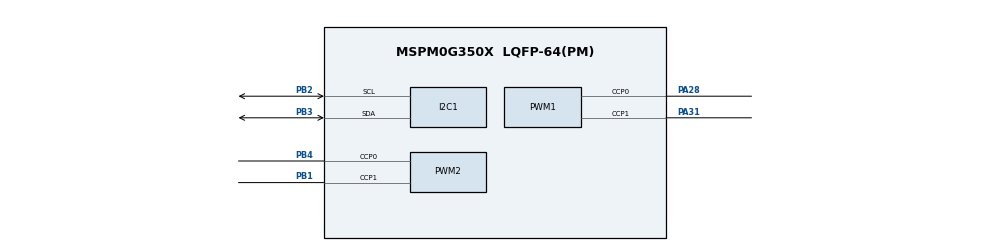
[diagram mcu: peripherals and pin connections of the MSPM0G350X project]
/**
 * @cliArgs --device "MSPM0G350X" --part "Default" --package "LQFP-64(PM)" --product "mspm0_sdk@2.05.01.01"
 * @versions {"tool":"1.24.0+4110"}
 */

/**
 * Import the modules used in this configuration.
 */
const GPIO          = scripting.addModule("/ti/driverlib/GPIO", {}, false);
const GPIO1         = GPIO.addInstance();
const GPIO2         = GPIO.addInstance();
const GPIO3         = GPIO.addInstance();
const GPIO4         = GPIO.addInstance();
const GPIO5         = GPIO.addInstance();
const GPIO6         = GPIO.addInstance();
const GPIO7         = GPIO.addInstance();
const GPIO8         = GPIO.addInstance();
const I2C           = scripting.addModule("/ti/driverlib/I2C", {}, false);
const I2C1          = I2C.addInstance();
const PWM           = scripting.addModule("/ti/driverlib/PWM", {}, false);
const PWM1          = PWM.addInstance();
const PWM2          = PWM.addInstance();
const SYSCTL        = scripting.addModule("/ti/driverlib/SYSCTL");
const TIMER         = scripting.addModule("/ti/driverlib/TIMER", {}, false);
const TIMER1        = TIMER.addInstance();
const TIMER2        = TIMER.addInstance();
const ProjectConfig = scripting.addModule("/ti/project_config/ProjectConfig");

/**
 * Write custom configuration values to the imported modules.
 */
GPIO1.$name                              = "GPIO_LED";
GPIO1.associatedPins.create(4);
GPIO1.associatedPins[0].$name            = "PIN_LED_1";
GPIO1.associatedPins[0].internalResistor = "PULL_UP";
GPIO1.associatedPins[0].assignedPort     = "PORTB";
GPIO1.associatedPins[0].assignedPin      = "22";
GPIO1.associatedPins[1].initialValue     = "SET";
GPIO1.associatedPins[1].assignedPort     = "PORTB";
GPIO1.associatedPins[1].$name            = "PIN_LED_2";
GPIO1.associatedPins[1].internalResistor = "PULL_UP";
GPIO1.associatedPins[1].assignedPin      = "26";
GPIO1.associatedPins[2].$name            = "PIN_LED_3";
GPIO1.associatedPins[2].internalResistor = "PULL_UP";
GPIO1.associatedPins[2].assignedPort     = "PORTB";
GPIO1.associatedPins[2].assignedPin      = "27";
GPIO1.associatedPins[3].assignedPort     = "PORTA";
GPIO1.associatedPins[3].assignedPin      = "13";
GPIO1.associatedPins[3].$name            = "LIGHT";

const Board = scripting.addModule("/ti/driverlib/Board", {}, false);

GPIO2.$name                              = "GPIO_KEY";
GPIO2.associatedPins.create(5);
GPIO2.associatedPins[0].$name            = "PIN_KEY_S2";
GPIO2.associatedPins[0].direction        = "INPUT";
GPIO2.associatedPins[0].assignedPort     = "PORTB";
GPIO2.associatedPins[0].assignedPin      = "21";
GPIO2.associatedPins[0].internalResistor = "PULL_UP";
GPIO2.associatedPins[1].$name            = "PIN_Key_K1";
GPIO2.associatedPins[1].direction        = "INPUT";
GPIO2.associatedPins[1].internalResistor = "PULL_UP";
GPIO2.associatedPins[1].assignedPort     = "PORTA";
GPIO2.associatedPins[1].assignedPin      = "15";
GPIO2.associatedPins[2].$name            = "PIN_Key_K2";
GPIO2.associatedPins[2].direction        = "INPUT";
GPIO2.associatedPins[2].internalResistor = "PULL_UP";
GPIO2.associatedPins[2].assignedPort     = "PORTA";
GPIO2.associatedPins[2].assignedPin      = "17";
GPIO2.associatedPins[3].$name            = "PIN_Key_K3";
GPIO2.associatedPins[3].direction        = "INPUT";
GPIO2.associatedPins[3].internalResistor = "PULL_UP";
GPIO2.associatedPins[3].assignedPort     = "PORTA";
GPIO2.associatedPins[3].assignedPin      = "24";
GPIO2.associatedPins[4].$name            = "PIN_Key_K4";
GPIO2.associatedPins[4].direction        = "INPUT";
GPIO2.associatedPins[4].internalResistor = "PULL_UP";
GPIO2.associatedPins[4].assignedPort     = "PORTB";
GPIO2.associatedPins[4].assignedPin      = "18";

GPIO3.$name                               = "GPIO_Motor_EXTI";
GPIO3.associatedPins.create(2);
GPIO3.associatedPins[0].assignedPort      = "PORTB";
GPIO3.associatedPins[0].assignedPin       = "20";
GPIO3.associatedPins[0].$name             = "M1_exti";
GPIO3.associatedPins[0].direction         = "INPUT";
GPIO3.associatedPins[0].interruptEn       = true;
GPIO3.associatedPins[0].interruptPriority = "1";
GPIO3.associatedPins[0].polarity          = "RISE";
GPIO3.associatedPins[0].internalResistor  = "PULL_DOWN";
GPIO3.associatedPins[1].$name             = "M2_exti";
GPIO3.associatedPins[1].direction         = "INPUT";
GPIO3.associatedPins[1].assignedPort      = "PORTB";
GPIO3.associatedPins[1].assignedPin       = "13";
GPIO3.associatedPins[1].interruptEn       = true;
GPIO3.associatedPins[1].interruptPriority = "1";
GPIO3.associatedPins[1].polarity          = "RISE";
GPIO3.associatedPins[1].internalResistor  = "PULL_DOWN";

GPIO4.$name                              = "GPIO_Grey";
GPIO4.associatedPins.create(8);
GPIO4.associatedPins[0].direction        = "INPUT";
GPIO4.associatedPins[0].internalResistor = "PULL_UP";
GPIO4.associatedPins[0].assignedPort     = "PORTB";
GPIO4.associatedPins[0].$name            = "PIN_Grey_0";
GPIO4.associatedPins[0].assignedPin      = "16";
GPIO4.associatedPins[1].direction        = "INPUT";
GPIO4.associatedPins[1].internalResistor = "PULL_UP";
GPIO4.associatedPins[1].assignedPort     = "PORTB";
GPIO4.associatedPins[1].$name            = "PIN_Grey_1";
GPIO4.associatedPins[1].assignedPin      = "0";
GPIO4.associatedPins[2].direction        = "INPUT";
GPIO4.associatedPins[2].internalResistor = "PULL_UP";
GPIO4.associatedPins[2].assignedPort     = "PORTB";
GPIO4.associatedPins[2].assignedPin      = "6";
GPIO4.associatedPins[2].$name            = "PIN_Grey_2";
GPIO4.associatedPins[3].direction        = "INPUT";
GPIO4.associatedPins[3].internalResistor = "PULL_UP";
GPIO4.associatedPins[3].assignedPort     = "PORTB";
GPIO4.associatedPins[3].$name            = "PIN_Grey_3";
GPIO4.associatedPins[3].assignedPin      = "7";
GPIO4.associatedPins[4].direction        = "INPUT";
GPIO4.associatedPins[4].internalResistor = "PULL_UP";
GPIO4.associatedPins[4].assignedPort     = "PORTB";
GPIO4.associatedPins[4].$name            = "PIN_Grey_4";
GPIO4.associatedPins[4].assignedPin      = "8";
GPIO4.associatedPins[5].$name            = "PIN_Grey_5";
GPIO4.associatedPins[5].direction        = "INPUT";
GPIO4.associatedPins[5].internalResistor = "PULL_UP";
GPIO4.associatedPins[5].assignedPort     = "PORTB";
GPIO4.associatedPins[5].assignedPin      = "19";
GPIO4.associatedPins[6].$name            = "PIN_Grey_6";
GPIO4.associatedPins[6].direction        = "INPUT";
GPIO4.associatedPins[6].internalResistor = "PULL_UP";
GPIO4.associatedPins[6].assignedPort     = "PORTA";
GPIO4.associatedPins[6].assignedPin      = "16";
GPIO4.associatedPins[7].$name            = "PIN_Grey_7";
GPIO4.associatedPins[7].direction        = "INPUT";
GPIO4.associatedPins[7].internalResistor = "PULL_UP";
GPIO4.associatedPins[7].assignedPort     = "PORTB";
GPIO4.associatedPins[7].assignedPin      = "12";

GPIO5.$name                          = "GPIO_Encoder";
GPIO5.associatedPins.create(2);
GPIO5.associatedPins[0].assignedPort = "PORTB";
GPIO5.associatedPins[0].$name        = "PIN_Encoder1";
GPIO5.associatedPins[0].assignedPin  = "15";
GPIO5.associatedPins[1].$name        = "PIN_Encoder2";
GPIO5.associatedPins[1].assignedPort = "PORTB";
GPIO5.associatedPins[1].assignedPin  = "17";

GPIO6.$name                          = "GPIO_Motor";
GPIO6.associatedPins.create(4);
GPIO6.associatedPins[0].$name        = "PIN_Motor1_1";
GPIO6.associatedPins[0].assignedPin  = "8";
GPIO6.associatedPins[0].assignedPort = "PORTA";
GPIO6.associatedPins[1].assignedPin  = "26";
GPIO6.associatedPins[1].assignedPort = "PORTA";
GPIO6.associatedPins[1].$name        = "PIN_Motor1_2";
GPIO6.associatedPins[2].$name        = "PIN_Motor2_1";
GPIO6.associatedPins[2].assignedPort = "PORTB";
GPIO6.associatedPins[2].assignedPin  = "24";
GPIO6.associatedPins[3].$name        = "PIN_Motor2_2";
GPIO6.associatedPins[3].assignedPort = "PORTB";
GPIO6.associatedPins[3].assignedPin  = "9";

GPIO7.$name                          = "GPIO_OLED";
GPIO7.associatedPins.create(2);
GPIO7.associatedPins[0].$name        = "OLED_SDA";
GPIO7.associatedPins[0].initialValue = "SET";
GPIO7.associatedPins[0].assignedPort = "PORTA";
GPIO7.associatedPins[0].assignedPin  = "25";
GPIO7.associatedPins[1].$name        = "OLED_SCL";
GPIO7.associatedPins[1].initialValue = "SET";
GPIO7.associatedPins[1].assignedPin  = "9";
GPIO7.associatedPins[1].assignedPort = "PORTA";

GPIO8.$name                          = "GPIO_Beep";
GPIO8.associatedPins[0].$name        = "Beep";
GPIO8.associatedPins[0].initialValue = "SET";
GPIO8.associatedPins[0].assignedPort = "PORTA";
GPIO8.associatedPins[0].assignedPin  = "12";

I2C1.$name                             = "I2C_MPU6050";
I2C1.basicEnableController             = true;
I2C1.intController                     = ["ARBITRATION_LOST","NACK","RXFIFO_TRIGGER","RX_DONE","TX_DONE"];
I2C1.peripheral.$assign                = "I2C1";
I2C1.peripheral.sdaPin.$assign         = "PB3";
I2C1.peripheral.sclPin.$assign         = "PB2";
I2C1.sdaPinConfig.hideOutputInversion  = scripting.forceWrite(false);
I2C1.sdaPinConfig.onlyInternalResistor = scripting.forceWrite(false);
I2C1.sdaPinConfig.passedPeripheralType = scripting.forceWrite("Digital");
I2C1.sdaPinConfig.$name                = "ti_driverlib_gpio_GPIOPinGeneric4";
I2C1.sclPinConfig.hideOutputInversion  = scripting.forceWrite(false);
I2C1.sclPinConfig.onlyInternalResistor = scripting.forceWrite(false);
I2C1.sclPinConfig.passedPeripheralType = scripting.forceWrite("Digital");
I2C1.sclPinConfig.$name                = "ti_driverlib_gpio_GPIOPinGeneric5";

PWM1.$name                              = "PWM_Motor";
PWM1.timerStartTimer                    = true;
PWM1.timerCount                         = 3200;
PWM1.peripheral.$assign                 = "TIMG7";
PWM1.peripheral.ccp0Pin.$assign         = "PA28";
PWM1.peripheral.ccp1Pin.$assign         = "PA31";
PWM1.PWM_CHANNEL_0.$name                = "ti_driverlib_pwm_PWMTimerCC0";
PWM1.PWM_CHANNEL_1.$name                = "ti_driverlib_pwm_PWMTimerCC1";
PWM1.ccp0PinConfig.direction            = scripting.forceWrite("OUTPUT");
PWM1.ccp0PinConfig.hideOutputInversion  = scripting.forceWrite(false);
PWM1.ccp0PinConfig.onlyInternalResistor = scripting.forceWrite(false);
PWM1.ccp0PinConfig.passedPeripheralType = scripting.forceWrite("Digital");
PWM1.ccp0PinConfig.$name                = "ti_driverlib_gpio_GPIOPinGeneric0";
PWM1.ccp1PinConfig.direction            = scripting.forceWrite("OUTPUT");
PWM1.ccp1PinConfig.hideOutputInversion  = scripting.forceWrite(false);
PWM1.ccp1PinConfig.onlyInternalResistor = scripting.forceWrite(false);
PWM1.ccp1PinConfig.passedPeripheralType = scripting.forceWrite("Digital");
PWM1.ccp1PinConfig.$name                = "ti_driverlib_gpio_GPIOPinGeneric1";

PWM2.$name                              = "PWM_Servo";
PWM2.clockDivider                       = 2;
PWM2.timerStartTimer                    = true;
PWM2.timerCount                         = 20000;
PWM2.clockPrescale                      = 16;
PWM2.pwmMode                            = "EDGE_ALIGN_UP";
PWM2.peripheral.$assign                 = "TIMA1";
PWM2.peripheral.ccp0Pin.$assign         = "PB4";
PWM2.peripheral.ccp1Pin.$assign         = "PB1";
PWM2.PWM_CHANNEL_0.$name                = "ti_driverlib_pwm_PWMTimerCC0_COPY";
PWM2.PWM_CHANNEL_0.dutyCycle            = 7.5;
PWM2.PWM_CHANNEL_1.$name                = "ti_driverlib_pwm_PWMTimerCC1_COPY";
PWM2.PWM_CHANNEL_1.dutyCycle            = 7.5;
PWM2.ccp0PinConfig.direction            = scripting.forceWrite("OUTPUT");
PWM2.ccp0PinConfig.hideOutputInversion  = scripting.forceWrite(false);
PWM2.ccp0PinConfig.onlyInternalResistor = scripting.forceWrite(false);
PWM2.ccp0PinConfig.passedPeripheralType = scripting.forceWrite("Digital");
PWM2.ccp0PinConfig.$name                = "ti_driverlib_gpio_GPIOPinGeneric0_COPY";
PWM2.ccp1PinConfig.direction            = scripting.forceWrite("OUTPUT");
PWM2.ccp1PinConfig.hideOutputInversion  = scripting.forceWrite(false);
PWM2.ccp1PinConfig.onlyInternalResistor = scripting.forceWrite(false);
PWM2.ccp1PinConfig.passedPeripheralType = scripting.forceWrite("Digital");
PWM2.ccp1PinConfig.$name                = "ti_driverlib_gpio_GPIOPinGeneric1_COPY";

SYSCTL.forceDefaultClkConfig = true;

TIMER1.timerClkPrescale   = 32;
TIMER1.timerMode          = "PERIODIC_UP";
TIMER1.interrupts         = ["LOAD"];
TIMER1.timerPeriod        = "10ms";
TIMER1.$name              = "ctrl";
TIMER1.timerStartTimer    = true;
TIMER1.interruptPriority  = "3";
TIMER1.peripheral.$assign = "TIMG6";

TIMER2.$name             = "circle";
TIMER2.timerMode         = "PERIODIC_UP";
TIMER2.timerClkPrescale  = 256;
TIMER2.interrupts        = ["LOAD"];
TIMER2.timerClkDiv       = 8;
TIMER2.interruptPriority = "0";
TIMER2.timerPeriod       = "3s";

/**
 * Pinmux solution for unlocked pins/peripherals. This ensures that minor changes to the automatic solver in a future
 * version of the tool will not impact the pinmux you originally saw.  These lines can be completely deleted in order to
 * re-solve from scratch.
 */
GPIO1.associatedPins[0].pin.$suggestSolution = "PB22";
GPIO1.associatedPins[1].pin.$suggestSolution = "PB26";
GPIO1.associatedPins[2].pin.$suggestSolution = "PB27";
GPIO1.associatedPins[3].pin.$suggestSolution = "PA13";
Board.peripheral.$suggestSolution            = "DEBUGSS";
Board.peripheral.swclkPin.$suggestSolution   = "PA20";
Board.peripheral.swdioPin.$suggestSolution   = "PA19";
GPIO2.associatedPins[0].pin.$suggestSolution = "PB21";
GPIO2.associatedPins[1].pin.$suggestSolution = "PA15";
GPIO2.associatedPins[2].pin.$suggestSolution = "PA17";
GPIO2.associatedPins[3].pin.$suggestSolution = "PA24";
GPIO2.associatedPins[4].pin.$suggestSolution = "PB18";
GPIO3.associatedPins[0].pin.$suggestSolution = "PB20";
GPIO3.associatedPins[1].pin.$suggestSolution = "PB13";
GPIO4.associatedPins[0].pin.$suggestSolution = "PB16";
GPIO4.associatedPins[1].pin.$suggestSolution = "PB0";
GPIO4.associatedPins[2].pin.$suggestSolution = "PB6";
GPIO4.associatedPins[3].pin.$suggestSolution = "PB7";
GPIO4.associatedPins[4].pin.$suggestSolution = "PB8";
GPIO4.associatedPins[5].pin.$suggestSolution = "PB19";
GPIO4.associatedPins[6].pin.$suggestSolution = "PA16";
GPIO4.associatedPins[7].pin.$suggestSolution = "PB12";
GPIO5.associatedPins[0].pin.$suggestSolution = "PB15";
GPIO5.associatedPins[1].pin.$suggestSolution = "PB17";
GPIO6.associatedPins[0].pin.$suggestSolution = "PA8";
GPIO6.associatedPins[1].pin.$suggestSolution = "PA26";
GPIO6.associatedPins[2].pin.$suggestSolution = "PB24";
GPIO6.associatedPins[3].pin.$suggestSolution = "PB9";
GPIO7.associatedPins[0].pin.$suggestSolution = "PA25";
GPIO7.associatedPins[1].pin.$suggestSolution = "PA9";
GPIO8.associatedPins[0].pin.$suggestSolution = "PA12";
SYSCTL.peripheral.$suggestSolution           = "SYSCTL";
TIMER2.peripheral.$suggestSolution           = "TIMA0";
